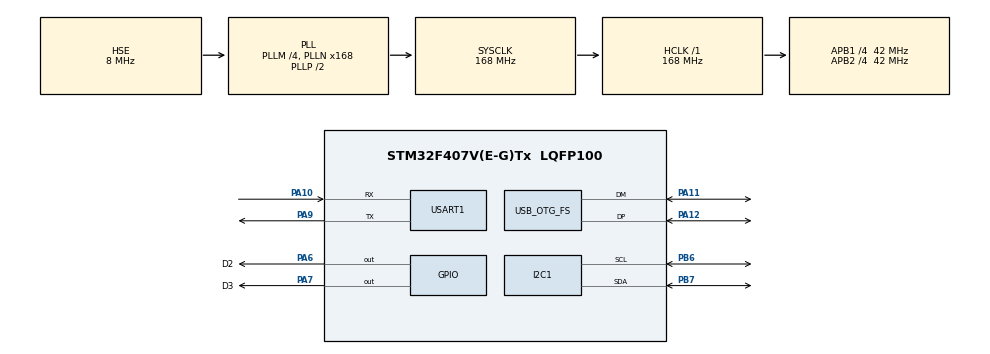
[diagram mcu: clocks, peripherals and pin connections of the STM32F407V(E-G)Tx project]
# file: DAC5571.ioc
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Dma.I2C1_RX.1.Direction=DMA_PERIPH_TO_MEMORY
Dma.I2C1_RX.1.FIFOMode=DMA_FIFOMODE_DISABLE
Dma.I2C1_RX.1.Instance=DMA1_Stream0
Dma.I2C1_RX.1.MemDataAlignment=DMA_MDATAALIGN_BYTE
Dma.I2C1_RX.1.MemInc=DMA_MINC_ENABLE
Dma.I2C1_RX.1.Mode=DMA_CIRCULAR
Dma.I2C1_RX.1.PeriphDataAlignment=DMA_PDATAALIGN_BYTE
Dma.I2C1_RX.1.PeriphInc=DMA_PINC_DISABLE
Dma.I2C1_RX.1.Priority=DMA_PRIORITY_LOW
Dma.I2C1_TX.2.Direction=DMA_MEMORY_TO_PERIPH
Dma.I2C1_TX.2.FIFOMode=DMA_FIFOMODE_DISABLE
Dma.I2C1_TX.2.Instance=DMA1_Stream6
Dma.I2C1_TX.2.MemDataAlignment=DMA_MDATAALIGN_BYTE
Dma.I2C1_TX.2.MemInc=DMA_MINC_ENABLE
Dma.I2C1_TX.2.Mode=DMA_CIRCULAR
Dma.I2C1_TX.2.PeriphDataAlignment=DMA_PDATAALIGN_BYTE
Dma.I2C1_TX.2.PeriphInc=DMA_PINC_DISABLE
Dma.I2C1_TX.2.Priority=DMA_PRIORITY_LOW
Dma.Request0=USART1_TX
Dma.Request1=I2C1_RX
Dma.Request2=I2C1_TX
Dma.USART1_TX.0.Direction=DMA_MEMORY_TO_PERIPH
Dma.USART1_TX.0.FIFOMode=DMA_FIFOMODE_DISABLE
Dma.USART1_TX.0.Instance=DMA2_Stream7
Dma.USART1_TX.0.MemDataAlignment=DMA_MDATAALIGN_BYTE
Dma.USART1_TX.0.MemInc=DMA_MINC_ENABLE
Dma.USART1_TX.0.Mode=DMA_NORMAL
Dma.USART1_TX.0.PeriphDataAlignment=DMA_PDATAALIGN_BYTE
Dma.USART1_TX.0.PeriphInc=DMA_PINC_DISABLE
Dma.USART1_TX.0.Priority=DMA_PRIORITY_LOW
Mcu.Family=STM32F4
Mcu.Name=STM32F407V(E-G)Tx
Mcu.Package=LQFP100
NVIC.DMA1_Stream0_IRQn=true\:0\:0\:false\:false\:true\:false
NVIC.DMA1_Stream6_IRQn=true\:0\:0\:false\:false\:true\:false
NVIC.DMA2_Stream7_IRQn=true\:0\:0\:false\:true\:true\:4\:false
NVIC.I2C1_EV_IRQn=true\:0\:0\:false\:false\:true\:true
NVIC.OTG_FS_IRQn=true\:0\:0\:false\:true\:true\:1\:false
NVIC.PriorityGroup=NVIC_PRIORITYGROUP_4
NVIC.TIM5_IRQn=true\:0\:0\:false\:true\:true\:2\:true
NVIC.USART1_IRQn=true\:0\:0\:false\:true\:true\:3\:true
PA10.Mode=Asynchronous
PA10.Signal=USART1_RX
PA11.Mode=Device_Only
PA11.Signal=USB_OTG_FS_DM
PA12.Mode=Device_Only
PA12.Signal=USB_OTG_FS_DP
PA13.Mode=Serial_Wire
PA13.Signal=SYS_JTMS-SWDIO
PA14.Mode=Serial_Wire
PA14.Signal=SYS_JTCK-SWCLK
PA6.GPIO_Label=D2
PA6.Signal=GPIO_Output
PA7.GPIO_Label=D3
PA7.Signal=GPIO_Output
PA9.Mode=Asynchronous
PA9.Signal=USART1_TX
PB6.Mode=I2C
PB6.Signal=I2C1_SCL
PB7.Mode=I2C
PB7.Signal=I2C1_SDA
PH0-OSC_IN.Mode=HSE-External-Oscillator
PH0-OSC_IN.Signal=RCC_OSC_IN
PH1-OSC_OUT.Mode=HSE-External-Oscillator
PH1-OSC_OUT.Signal=RCC_OSC_OUT
ProjectManager.HeapSize=0x200
ProjectManager.StackSize=0x400
ProjectManager.TargetToolchain=EWARM
RCC.48MHZClocksFreq_Value=48000000
RCC.AHBFreq_Value=168000000
RCC.APB1CLKDivider=RCC_HCLK_DIV4
RCC.APB1Freq_Value=42000000
RCC.APB1TimFreq_Value=84000000
RCC.APB2CLKDivider=RCC_HCLK_DIV4
RCC.APB2Freq_Value=42000000
RCC.APB2TimFreq_Value=84000000
RCC.CortexFreq_Value=168000000
RCC.HCLKFreq_Value=168000000
RCC.HSE_VALUE=8000000
RCC.HSI_VALUE=16000000
RCC.LSE_VALUE=32768
RCC.PLLM=4
RCC.PLLN=168
RCC.PLLQ=7
RCC.SYSCLKFreq_VALUE=168000000
RCC.SYSCLKSource=RCC_SYSCLKSOURCE_PLLCLK
RCC.VCOOutputFreq_Value=336000000
TIM5.Period=1000 - 1
TIM5.Prescaler=84
USART1.VirtualMode=VM_ASYNC
USB_DEVICE.CLASS_NAME_FS=CDC
USB_DEVICE.VirtualMode-CDC_FS=Cdc
USB_DEVICE.VirtualModeFS=Cdc_FS
USB_OTG_FS.VirtualMode=Device_Only
VP_TIM5_VS_ClockSourceINT.Mode=Internal
VP_USB_DEVICE_VS_USB_DEVICE_CDC_FS.Mode=CDC_FS
board=DAC5571

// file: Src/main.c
/**
  ******************************************************************************
  * File Name          : main.c
  * Description        : Main program body
  ******************************************************************************
  * This notice applies to any and all portions of this file
  * that are not between comment pairs USER CODE BEGIN and
  * USER CODE END. Other portions of this file, whether
  * inserted by the user or by software development tools
  * are owned by their respective copyright owners.
  *
  * Copyright (c) 2017 STMicroelectronics International N.V.
  * All rights reserved.
  *
  * Redistribution and use in source and binary forms, with or without
  * modification, are permitted, provided that the following conditions are met:
  *
  * 1. Redistribution of source code must retain the above copyright notice,
  *    this list of conditions and the following disclaimer.
  * 2. Redistributions in binary form must reproduce the above copyright notice,
  *    this list of conditions and the following disclaimer in the documentation
  *    and/or other materials provided with the distribution.
  * 3. Neither the name of STMicroelectronics nor the names of other
  *    contributors to this software may be used to endorse or promote products
  *    derived from this software without specific written permission.
  * 4. This software, including modifications and/or derivative works of this
  *    software, must execute solely and exclusively on microcontroller or
  *    microprocessor devices manufactured by or for STMicroelectronics.
  * 5. Redistribution and use of this software other than as permitted under
  *    this license is void and will automatically terminate your rights under
  *    this license.
  *
  * THIS SOFTWARE IS PROVIDED BY STMICROELECTRONICS AND CONTRIBUTORS "AS IS"
  * AND ANY EXPRESS, IMPLIED OR STATUTORY WARRANTIES, INCLUDING, BUT NOT
  * LIMITED TO, THE IMPLIED WARRANTIES OF MERCHANTABILITY, FITNESS FOR A
  * PARTICULAR PURPOSE AND NON-INFRINGEMENT OF THIRD PARTY INTELLECTUAL PROPERTY
  * RIGHTS ARE DISCLAIMED TO THE FULLEST EXTENT PERMITTED BY LAW. IN NO EVENT
  * SHALL STMICROELECTRONICS OR CONTRIBUTORS BE LIABLE FOR ANY DIRECT, INDIRECT,
  * INCIDENTAL, SPECIAL, EXEMPLARY, OR CONSEQUENTIAL DAMAGES (INCLUDING, BUT NOT
  * LIMITED TO, PROCUREMENT OF SUBSTITUTE GOODS OR SERVICES; LOSS OF USE, DATA,
  * OR PROFITS; OR BUSINESS INTERRUPTION) HOWEVER CAUSED AND ON ANY THEORY OF
  * LIABILITY, WHETHER IN CONTRACT, STRICT LIABILITY, OR TORT (INCLUDING
  * NEGLIGENCE OR OTHERWISE) ARISING IN ANY WAY OUT OF THE USE OF THIS SOFTWARE,
  * EVEN IF ADVISED OF THE POSSIBILITY OF SUCH DAMAGE.
  *
  ******************************************************************************
  */

#include "main.h"
#include "stm32f4xx_hal.h"
#include "dma.h"
#include "i2c.h"
#include "tim.h"
#include "usart.h"
#include "usb_device.h"
#include "gpio.h"

/* USER CODE BEGIN PV */
/* Private variables ---------------------------------------------------------*/
#define DAC5571_ADDR_Write              0x98
#define DAC5571_ADDR-Read               0x99

uint8_t gDACbuffer[2] = {0x00,0xFF};

/* USER CODE END PV */

void SystemClock_Config(void);
static void MX_NVIC_Init(void);

/* USER CODE BEGIN PFP */
/* Private function prototypes -----------------------------------------------*/

/* USER CODE END PFP */

int main(void)
{

  /* MCU Configuration----------------------------------------------------------*/

  /* Reset of all peripherals, Initializes the Flash interface and the Systick. */
  HAL_Init();

  /* Configure the system clock */
  SystemClock_Config();

  /* Initialize all configured peripherals */
  MX_GPIO_Init();
  MX_DMA_Init();
  MX_TIM5_Init();
  MX_USART1_UART_Init();
  MX_USB_DEVICE_Init();
  MX_I2C1_Init();

  /* Initialize interrupts */
  MX_NVIC_Init();

  /* USER CODE BEGIN 2 */
  HAL_TIM_Base_Start_IT(&htim5);
  HAL_I2C_Master_Transmit(&hi2c1,DAC5571_ADDR_Write,gDACbuffer,2,0xFFFF);

  /* USER CODE END 2 */

  /* Infinite loop */
  while (1)
  {

  /* USER CODE BEGIN 3 */
    printf("\r\n welcome to STMF407xx \r\n");
    HAL_Delay(500);

  }
  /* USER CODE END 3 */

}

/** System Clock Configuration
*/
void SystemClock_Config(void)
{

  RCC_OscInitTypeDef RCC_OscInitStruct;
  RCC_ClkInitTypeDef RCC_ClkInitStruct;

    /**Configure the main internal regulator output voltage
    */
  __HAL_RCC_PWR_CLK_ENABLE();

  __HAL_PWR_VOLTAGESCALING_CONFIG(PWR_REGULATOR_VOLTAGE_SCALE1);

    /**Initializes the CPU, AHB and APB busses clocks
    */
  RCC_OscInitStruct.OscillatorType = RCC_OSCILLATORTYPE_HSE;
  RCC_OscInitStruct.HSEState = RCC_HSE_ON;
  RCC_OscInitStruct.PLL.PLLState = RCC_PLL_ON;
  RCC_OscInitStruct.PLL.PLLSource = RCC_PLLSOURCE_HSE;
  RCC_OscInitStruct.PLL.PLLM = 4;
  RCC_OscInitStruct.PLL.PLLN = 168;
  RCC_OscInitStruct.PLL.PLLP = RCC_PLLP_DIV2;
  RCC_OscInitStruct.PLL.PLLQ = 7;
  if (HAL_RCC_OscConfig(&RCC_OscInitStruct) != HAL_OK)
  {
    _Error_Handler(__FILE__, __LINE__);
  }

    /**Initializes the CPU, AHB and APB busses clocks
    */
  RCC_ClkInitStruct.ClockType = RCC_CLOCKTYPE_HCLK|RCC_CLOCKTYPE_SYSCLK
                              |RCC_CLOCKTYPE_PCLK1|RCC_CLOCKTYPE_PCLK2;
  RCC_ClkInitStruct.SYSCLKSource = RCC_SYSCLKSOURCE_PLLCLK;
  RCC_ClkInitStruct.AHBCLKDivider = RCC_SYSCLK_DIV1;
  RCC_ClkInitStruct.APB1CLKDivider = RCC_HCLK_DIV4;
  RCC_ClkInitStruct.APB2CLKDivider = RCC_HCLK_DIV4;

  if (HAL_RCC_ClockConfig(&RCC_ClkInitStruct, FLASH_LATENCY_5) != HAL_OK)
  {
    _Error_Handler(__FILE__, __LINE__);
  }

    /**Configure the Systick interrupt time
    */
  HAL_SYSTICK_Config(HAL_RCC_GetHCLKFreq()/1000);

    /**Configure the Systick
    */
  HAL_SYSTICK_CLKSourceConfig(SYSTICK_CLKSOURCE_HCLK);

  /* SysTick_IRQn interrupt configuration */
  HAL_NVIC_SetPriority(SysTick_IRQn, 0, 0);
}

/** NVIC Configuration
*/
static void MX_NVIC_Init(void)
{
  /* OTG_FS_IRQn interrupt configuration */
  HAL_NVIC_SetPriority(OTG_FS_IRQn, 0, 0);
  HAL_NVIC_EnableIRQ(OTG_FS_IRQn);
  /* TIM5_IRQn interrupt configuration */
  HAL_NVIC_SetPriority(TIM5_IRQn, 0, 0);
  HAL_NVIC_EnableIRQ(TIM5_IRQn);
  /* USART1_IRQn interrupt configuration */
  HAL_NVIC_SetPriority(USART1_IRQn, 0, 0);
  HAL_NVIC_EnableIRQ(USART1_IRQn);
  /* DMA2_Stream7_IRQn interrupt configuration */
  HAL_NVIC_SetPriority(DMA2_Stream7_IRQn, 0, 0);
  HAL_NVIC_EnableIRQ(DMA2_Stream7_IRQn);
}

/* USER CODE BEGIN 4 */
/**
  * @brief  Period elapsed callback in non blocking mode
  * @param  htim pointer to a TIM_HandleTypeDef structure that contains
  *                the configuration information for TIM module.
  * @retval None
  */
void HAL_TIM_PeriodElapsedCallback(TIM_HandleTypeDef *htim)
{
  /* Prevent unused argument(s) compilation warning */
  UNUSED(htim);
  /* NOTE : This function Should not be modified, when the callback is needed,
            the __HAL_TIM_PeriodElapsedCallback could be implemented in the user file
   */
  if(htim5.Instance ==  htim->Instance)
  {
    HAL_GPIO_TogglePin(GPIOA,D2_Pin);
  }
}

/* USER CODE END 4 */

void _Error_Handler(char * file, int line)
{
  while(1)
  {
  }
}

/************************ (C) COPYRIGHT STMicroelectronics *****END OF FILE****/
